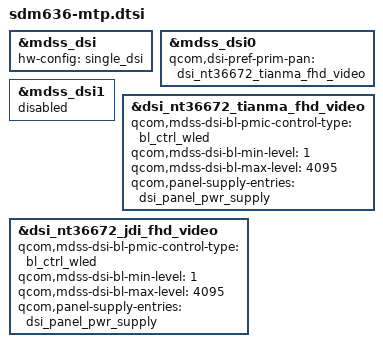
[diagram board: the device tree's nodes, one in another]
/* Copyright (c) 2017, The Linux Foundation. All rights reserved.
 * Copyright (C) 2019 XiaoMi, Inc.
 *
 * This program is free software; you can redistribute it and/or modify
 * it under the terms of the GNU General Public License version 2 and
 * only version 2 as published by the Free Software Foundation.
 *
 * This program is distributed in the hope that it will be useful,
 * but WITHOUT ANY WARRANTY; without even the implied warranty of
 * MERCHANTABILITY or FITNESS FOR A PARTICULAR PURPOSE.  See the
 * GNU General Public License for more details.
 */

#include "sdm660-mtp.dtsi"
#include "sdm636-camera-sensor-mtp.dtsi"
/ {
};

&mdss_dsi {
	hw-config = "single_dsi";
};

&mdss_dsi0 {
	qcom,dsi-pref-prim-pan = <&dsi_nt36672_tianma_fhd_video>;
};

&mdss_dsi1 {
	status = "disabled";
};

&dsi_nt36672_tianma_fhd_video {
	qcom,mdss-dsi-bl-pmic-control-type = "bl_ctrl_wled";
	qcom,mdss-dsi-bl-min-level = <1>;
	qcom,mdss-dsi-bl-max-level = <4095>;
	qcom,panel-supply-entries = <&dsi_panel_pwr_supply>;
};

&dsi_nt36672_jdi_fhd_video {
	qcom,mdss-dsi-bl-pmic-control-type = "bl_ctrl_wled";
	qcom,mdss-dsi-bl-min-level = <1>;
	qcom,mdss-dsi-bl-max-level = <4095>;
	qcom,panel-supply-entries = <&dsi_panel_pwr_supply>;
};

